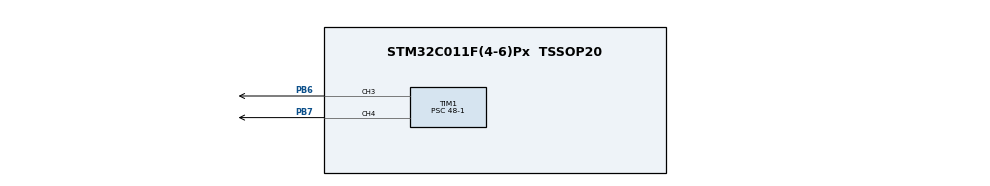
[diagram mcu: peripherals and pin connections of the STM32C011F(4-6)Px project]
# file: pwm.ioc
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Mcu.Family=STM32C0
Mcu.Name=STM32C011F(4-6)Px
Mcu.Package=TSSOP20
PA13.Mode=Serial_Wire
PA13.Signal=DEBUG_SWDIO
PA14-BOOT0.Mode=Serial_Wire
PA14-BOOT0.Signal=DEBUG_SWCLK
PB6.Signal=S_TIM1_CH3
PB7.Signal=S_TIM1_CH4
ProjectManager.HeapSize=0x200
ProjectManager.StackSize=0x400
ProjectManager.TargetToolchain=STM32CubeIDE
RCC.ADCFreq_Value=48000000
RCC.AHBFreq_Value=48000000
RCC.CortexFreq_Value=48000000
RCC.EXTERNAL_CLOCK_VALUE=12288000
RCC.HCLKFreq_Value=48000000
RCC.HSE_VALUE=8000000
RCC.HSISYSCLKDivider=RCC_HSI_DIV1
RCC.HSI_VALUE=48000000
RCC.LSE_VALUE=32768
RCC.SYSCLKFreq_VALUE=48000000
SH.S_TIM1_CH3.0=TIM1_CH3,PWM Generation3 CH3
SH.S_TIM1_CH4.0=TIM1_CH4,PWM Generation4 CH4
TIM1.Channel-PWM\ Generation3\ CH3=TIM_CHANNEL_3
TIM1.Channel-PWM\ Generation4\ CH4=TIM_CHANNEL_4
TIM1.Period=1000-1
TIM1.Prescaler=48-1
VP_TIM1_VS_ClockSourceINT.Mode=Internal
board=custom

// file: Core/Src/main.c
/* USER CODE BEGIN Header */
/**
  ******************************************************************************
  * @file           : main.c
  * @brief          : Main program body
  ******************************************************************************
  * @attention
  *
  * Copyright (c) 2024 STMicroelectronics.
  * All rights reserved.
  *
  * This software is licensed under terms that can be found in the LICENSE file
  * in the root directory of this software component.
  * If no LICENSE file comes with this software, it is provided AS-IS.
  *
  ******************************************************************************
  */
/* USER CODE END Header */
#include "main.h"

TIM_HandleTypeDef htim1;

void SystemClock_Config(void);
static void MX_GPIO_Init(void);
static void MX_TIM1_Init(void);
void atualiza_largura_puslo_LEDS(int start, int end, int step);

/* USER CODE BEGIN 0 */
void atualiza_largura_puslo_LEDS(int start, int end, int step) {
    for (int i = start; i != end; i += step) {
        int LED1_pulse = i;
        int LED2_pulse = 1000 - i;

        __HAL_TIM_SET_COMPARE(&htim1, TIM_CHANNEL_3, LED1_pulse); // (PB6, LED1)
        __HAL_TIM_SET_COMPARE(&htim1, TIM_CHANNEL_4, LED2_pulse); // (PB7, LED2)

        HAL_Delay(1);
    }
}
/* USER CODE END 0 */

int main(void)
{

  /* MCU Configuration--------------------------------------------------------*/

  /* Reset of all peripherals, Initializes the Flash interface and the Systick. */
  HAL_Init();

  /* Configure the system clock */
  SystemClock_Config();

  /* Initialize all configured peripherals */
  MX_GPIO_Init();
  MX_TIM1_Init();
  /* USER CODE BEGIN 2 */
  HAL_TIM_PWM_Start(&htim1, TIM_CHANNEL_3);	// Inicia Timer 1 para geração de PWM no canais 3 (PB6, LED1)
  HAL_TIM_PWM_Start(&htim1, TIM_CHANNEL_4);	// Inicia Timer 1 para geração de PWM no canais 4 (PB7, LED2)
  /* USER CODE END 2 */

  /* Infinite loop */
  while (1)
  {

    /* USER CODE BEGIN 3 */
	// Aumenta gradualmente a largura de pulso no LED1 e diminui no LED2
	atualiza_largura_puslo_LEDS(0, 1000, 1);

	// Diminui gradualmente a largura de pulso no LED1 e aumenta no LED2
	atualiza_largura_puslo_LEDS(1000, 0, -1);
  }
  /* USER CODE END 3 */
}

void SystemClock_Config(void)
{
  RCC_OscInitTypeDef RCC_OscInitStruct = {0};
  RCC_ClkInitTypeDef RCC_ClkInitStruct = {0};

  /** Initializes the RCC Oscillators according to the specified parameters
  * in the RCC_OscInitTypeDef structure.
  */
  RCC_OscInitStruct.OscillatorType = RCC_OSCILLATORTYPE_HSI;
  RCC_OscInitStruct.HSIState = RCC_HSI_ON;
  RCC_OscInitStruct.HSIDiv = RCC_HSI_DIV1;
  RCC_OscInitStruct.HSICalibrationValue = RCC_HSICALIBRATION_DEFAULT;
  if (HAL_RCC_OscConfig(&RCC_OscInitStruct) != HAL_OK)
  {
    Error_Handler();
  }

  /** Initializes the CPU, AHB and APB buses clocks
  */
  RCC_ClkInitStruct.ClockType = RCC_CLOCKTYPE_HCLK|RCC_CLOCKTYPE_SYSCLK
                              |RCC_CLOCKTYPE_PCLK1;
  RCC_ClkInitStruct.SYSCLKSource = RCC_SYSCLKSOURCE_HSI;
  RCC_ClkInitStruct.SYSCLKDivider = RCC_SYSCLK_DIV1;
  RCC_ClkInitStruct.AHBCLKDivider = RCC_HCLK_DIV1;
  RCC_ClkInitStruct.APB1CLKDivider = RCC_APB1_DIV1;

  if (HAL_RCC_ClockConfig(&RCC_ClkInitStruct, FLASH_LATENCY_1) != HAL_OK)
  {
    Error_Handler();
  }
}

static void MX_TIM1_Init(void)
{

  TIM_ClockConfigTypeDef sClockSourceConfig = {0};
  TIM_MasterConfigTypeDef sMasterConfig = {0};
  TIM_OC_InitTypeDef sConfigOC = {0};
  TIM_BreakDeadTimeConfigTypeDef sBreakDeadTimeConfig = {0};

  htim1.Instance = TIM1;
  htim1.Init.Prescaler = 48-1;
  htim1.Init.CounterMode = TIM_COUNTERMODE_UP;
  htim1.Init.Period = 1000-1;
  htim1.Init.ClockDivision = TIM_CLOCKDIVISION_DIV1;
  htim1.Init.RepetitionCounter = 0;
  htim1.Init.AutoReloadPreload = TIM_AUTORELOAD_PRELOAD_DISABLE;
  if (HAL_TIM_Base_Init(&htim1) != HAL_OK)
  {
    Error_Handler();
  }
  sClockSourceConfig.ClockSource = TIM_CLOCKSOURCE_INTERNAL;
  if (HAL_TIM_ConfigClockSource(&htim1, &sClockSourceConfig) != HAL_OK)
  {
    Error_Handler();
  }
  if (HAL_TIM_PWM_Init(&htim1) != HAL_OK)
  {
    Error_Handler();
  }
  sMasterConfig.MasterOutputTrigger = TIM_TRGO_RESET;
  sMasterConfig.MasterOutputTrigger2 = TIM_TRGO2_RESET;
  sMasterConfig.MasterSlaveMode = TIM_MASTERSLAVEMODE_DISABLE;
  if (HAL_TIMEx_MasterConfigSynchronization(&htim1, &sMasterConfig) != HAL_OK)
  {
    Error_Handler();
  }
  sConfigOC.OCMode = TIM_OCMODE_PWM1;
  sConfigOC.Pulse = 0;
  sConfigOC.OCPolarity = TIM_OCPOLARITY_HIGH;
  sConfigOC.OCNPolarity = TIM_OCNPOLARITY_HIGH;
  sConfigOC.OCFastMode = TIM_OCFAST_DISABLE;
  sConfigOC.OCIdleState = TIM_OCIDLESTATE_RESET;
  sConfigOC.OCNIdleState = TIM_OCNIDLESTATE_RESET;
  if (HAL_TIM_PWM_ConfigChannel(&htim1, &sConfigOC, TIM_CHANNEL_3) != HAL_OK)
  {
    Error_Handler();
  }
  if (HAL_TIM_PWM_ConfigChannel(&htim1, &sConfigOC, TIM_CHANNEL_4) != HAL_OK)
  {
    Error_Handler();
  }
  sBreakDeadTimeConfig.OffStateRunMode = TIM_OSSR_DISABLE;
  sBreakDeadTimeConfig.OffStateIDLEMode = TIM_OSSI_DISABLE;
  sBreakDeadTimeConfig.LockLevel = TIM_LOCKLEVEL_OFF;
  sBreakDeadTimeConfig.DeadTime = 0;
  sBreakDeadTimeConfig.BreakState = TIM_BREAK_DISABLE;
  sBreakDeadTimeConfig.BreakPolarity = TIM_BREAKPOLARITY_HIGH;
  sBreakDeadTimeConfig.BreakFilter = 0;
  sBreakDeadTimeConfig.BreakAFMode = TIM_BREAK_AFMODE_INPUT;
  sBreakDeadTimeConfig.Break2State = TIM_BREAK2_DISABLE;
  sBreakDeadTimeConfig.Break2Polarity = TIM_BREAK2POLARITY_HIGH;
  sBreakDeadTimeConfig.Break2Filter = 0;
  sBreakDeadTimeConfig.Break2AFMode = TIM_BREAK_AFMODE_INPUT;
  sBreakDeadTimeConfig.AutomaticOutput = TIM_AUTOMATICOUTPUT_DISABLE;
  if (HAL_TIMEx_ConfigBreakDeadTime(&htim1, &sBreakDeadTimeConfig) != HAL_OK)
  {
    Error_Handler();
  }
  HAL_TIM_MspPostInit(&htim1);

}

static void MX_GPIO_Init(void)
{

  /* GPIO Ports Clock Enable */
  __HAL_RCC_GPIOB_CLK_ENABLE();
  __HAL_RCC_GPIOA_CLK_ENABLE();

}

void Error_Handler(void)
{
  __disable_irq();
  while (1)
  {
  }
}
